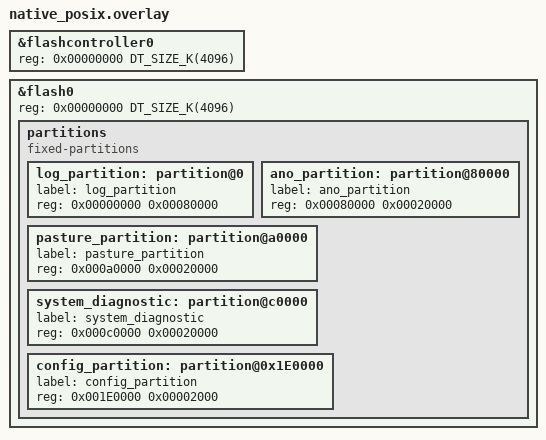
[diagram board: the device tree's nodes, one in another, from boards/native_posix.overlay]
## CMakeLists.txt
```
#
# Copyright (c) 2022 Nofence AS
#

cmake_minimum_required(VERSION 3.20.0)

list(APPEND ZEPHYR_EXTRA_MODULES
        ${CMAKE_CURRENT_SOURCE_DIR}/../../src/modules/collar_protocol
        )

find_package(Zephyr REQUIRED HINTS $ENV{ZEPHYR_BASE})
project(storage_controller)

zephyr_include_directories(${CMAKE_CURRENT_BINARY_DIR})
include_directories(${CMAKE_CURRENT_BINARY_DIR})

FILE(GLOB app_sources 
        ${CMAKE_CURRENT_SOURCE_DIR}/src/*.c 
        ${CMAKE_CURRENT_SOURCE_DIR}/mock/*.c 
        ${CMAKE_CURRENT_SOURCE_DIR}/../../src/events/storage/*.c
        ${CMAKE_CURRENT_SOURCE_DIR}/../../src/modules/storage_controller/storage.c
        ${CMAKE_CURRENT_SOURCE_DIR}/../../src/modules/storage_controller/fcb_ext/*.c
        ${CMAKE_CURRENT_SOURCE_DIR}/../../src/modules/storage/*.c
        ${CMAKE_CURRENT_SOURCE_DIR}/../../src/events/error_handler/*.c
        ${CMAKE_CURRENT_SOURCE_DIR}/../../src/events/messaging/*.c
)
target_sources(app PRIVATE ${app_sources})
target_include_directories(app PRIVATE ${APP_SOURCE})

zephyr_library_include_directories(
  ${CMAKE_CURRENT_SOURCE_DIR}/src/
  ${CMAKE_CURRENT_SOURCE_DIR}/mock/
  ${CMAKE_CURRENT_SOURCE_DIR}/../../src/modules/storage_controller/
  ${CMAKE_CURRENT_SOURCE_DIR}/../../src/modules/storage_controller/include
  ${CMAKE_CURRENT_SOURCE_DIR}/../../src/modules/storage_controller/fcb_ext
  ${CMAKE_CURRENT_SOURCE_DIR}/../../src/events/storage
  ${CMAKE_CURRENT_SOURCE_DIR}/../../src/events/error_handler
  ${CMAKE_CURRENT_SOURCE_DIR}/../../src/events/messaging
  ${CMAKE_CURRENT_SOURCE_DIR}/../../src/modules/messaging
  ${CMAKE_CURRENT_SOURCE_DIR}/../../include
  #${CMAKE_CURRENT_SOURCE_DIR}/../../src/modules/nf_settings/include
)
add_dependencies(app collar_protocol_headers)
```

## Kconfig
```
menu "APPLICATION_CODE"
	menu "Storage controller"
    	rsource "./../../src/modules/storage_controller/Kconfig"
	endmenu # Storage controller
	menu "ERROR_HANDLER"
    	rsource "./../../src/modules/error_handler/Kconfig"
	endmenu # ERROR_HANDLER
endmenu # APPLICATION CODE

menu "Zephyr Kernel"
source "Kconfig.zephyr"
endmenu
```

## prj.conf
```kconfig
CONFIG_ZTEST=y
CONFIG_ZTEST_MOCKING=y
CONFIG_ZTEST_STACKSIZE=8192

# Configuration required by Event Manager
CONFIG_EVENT_MANAGER=y
CONFIG_LINKER_ORPHAN_SECTION_PLACE=y
CONFIG_SYSTEM_WORKQUEUE_STACK_SIZE=16384
CONFIG_HEAP_MEM_POOL_SIZE=16384
CONFIG_REBOOT=y

CONFIG_MAIN_STACK_SIZE=8192
CONFIG_FLASH=y
CONFIG_FLASH_PAGE_LAYOUT=y
CONFIG_FLASH_MAP=y
CONFIG_FCB=y
CONFIG_NVS=n

# For rand()
CONFIG_NEWLIB_LIBC=y 

CONFIG_COLLAR_PROTOCOL=y
```

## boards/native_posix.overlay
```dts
&flashcontroller0 {
        reg = <0x00000000 DT_SIZE_K(4096)>;
};

&flash0 {
        reg = <0x00000000 DT_SIZE_K(4096)>;
        partitions {
                compatible = "fixed-partitions";
                #address-cells = <1>;
                #size-cells = <1>;

                log_partition: partition@0 {
                        label = "log_partition";
                        reg = <0x00000000 0x00080000>;
                };
                ano_partition: partition@80000 {
                        label = "ano_partition";
                        reg = <0x00080000 0x00020000>;
                };
                pasture_partition: partition@a0000 {
                        label = "pasture_partition";
                        reg = <0x000a0000 0x00020000>;
                };
                system_diagnostic: partition@c0000 {
                        label = "system_diagnostic";
                        reg = <0x000c0000 0x00020000>;
                };

                config_partition: partition@0x1E0000 {
                        label = "config_partition";
                        reg = <0x001E0000 0x00002000>;
                };
        };
};
```

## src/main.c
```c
/*
 * Copyright (c) 2022 Nofence AS
 */

#include <ztest.h>
#include "storage.h"
#include "storage_event.h"
#include "storage_helper.h"
#include "error_event.h"
#include "ano_structure.h"
#include "log_structure.h"
#include "pasture_structure.h"

/* Provide custom assert post action handler to handle the assertion on OOM
 * error in Event Manager.
 */
BUILD_ASSERT(!IS_ENABLED(CONFIG_ASSERT_NO_FILE_INFO));
void assert_post_action(const char *file, unsigned int line)
{
	printk("assert_post_action - file: %s (line: %u)\n", file, line);
}

void test_event_manager_init(void)
{
	zassert_false(event_manager_init(), "Error when initializing event manager");
}

void test_init(void)
{
	zassert_false(stg_init_storage_controller(), "Error when initializing storage controller.");
	init_dummy_pasture();
}

void test_main(void)
{
	/* Init FCBs and event manager setup. */
	ztest_test_suite(storage_init, ztest_unit_test(test_event_manager_init),
			 ztest_unit_test(test_init));
	ztest_run_test_suite(storage_init);

	/* Test log partition. */
	ztest_test_suite(storage_log_test, ztest_unit_test(test_log),
			 ztest_unit_test(test_log_padding),
			 ztest_unit_test(test_reboot_persistent_log),
			 ztest_unit_test(test_log_extended), ztest_unit_test(test_no_log_available),
			 ztest_unit_test(test_log_after_reboot), ztest_unit_test(test_double_clear),
			 ztest_unit_test(test_rotate_handling));
	ztest_run_test_suite(storage_log_test);

	/* Test ano partition. */
	ztest_test_suite(storage_ano_test, ztest_unit_test(test_ano_write_20_days),
			 ztest_unit_test(test_ano_write_sent), ztest_unit_test(test_ano_write_all),
			 ztest_unit_test(test_no_ano_available),
			 ztest_unit_test(test_reboot_persistent_ano));
	ztest_run_test_suite(storage_ano_test);

	/* Test pasture partition. */
	ztest_test_suite(storage_pasture_test, ztest_unit_test(test_pasture),
			 ztest_unit_test(test_reboot_persistent_pasture),
			 ztest_unit_test(test_pasture_extended_write_read),
			 ztest_unit_test(test_request_pasture_multiple),
			 ztest_unit_test(test_no_pasture_available));
	ztest_run_test_suite(storage_pasture_test);

	/* Test system diagnostic partition. */
	ztest_test_suite(storage_sys_diag_test, ztest_unit_test(test_sys_diag_log),
			 ztest_unit_test(test_reboot_persistent_system_diag));
	ztest_run_test_suite(storage_sys_diag_test);
}

static bool event_handler(const struct event_header *eh)
{
	if (is_error_event(eh)) {
		printk("Error detected. \n");
	}
	return false;
}

EVENT_LISTENER(test_main, event_handler);
EVENT_SUBSCRIBE(test_main, error_event);
EVENT_SUBSCRIBE(test_main, pasture_ready_event);
```

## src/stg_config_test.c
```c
/*
 * Copyright (c) 2022 Nofence AS
 */

#include <ztest.h>
#include "storage_helper.h"
#include "stg_config.h"
#include "pm_config.h"

void test_stg_init()
{
    zassert_equal(stg_config_init(), 0, "");
}
```

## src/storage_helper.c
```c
#include <ztest.h>
#include "storage.h"
#include "pasture_event.h"
#include "storage_helper.h"

#include "ano_structure.h"
#include "log_structure.h"
#include "pasture_structure.h"
```

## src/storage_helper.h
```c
/*
 * Copyright (c) 2022 Nofence AS
 */

#ifndef _STORAGE_HELPER_H_
#define _STORAGE_HELPER_H_

#include <ztest.h>
#include "storage.h"

void init_dummy_pasture(void);

/* Pasture tests. */
void test_pasture(void);
void test_pasture_extended_write_read(void);
void test_reboot_persistent_pasture(void);
void test_request_pasture_multiple(void);
void test_no_pasture_available(void);

/* Log tests. */
void test_log(void);
void test_log_extended(void);
void test_reboot_persistent_log(void);
void test_no_log_available(void);
void test_log_after_reboot(void);
void test_double_clear(void);
void test_rotate_handling(void);
void test_log_padding(void);

/* Ano tests. */
void test_ano_write_20_days(void);
void test_ano_write_sent(void);
void test_no_ano_available(void);
void test_ano_write_all(void);
void test_reboot_persistent_ano(void);

/* System diagnostic tests. */
void test_sys_diag_log(void);
void test_reboot_persistent_system_diag(void);

#endif /* _STORAGE_HELPER_H_ */
```

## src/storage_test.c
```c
/*
 * Copyright (c) 2022 Nofence AS
 */

#include <ztest.h>
#include "storage.h"
#include "storage_events.h"
#include "storage_helper.h"

#include "ano_structure.h"
#include "log_structure.h"
#include "pasture_structure.h"

K_SEM_DEFINE(write_log_ack_sem, 0, 1);
K_SEM_DEFINE(read_log_ack_sem, 0, 1);
K_SEM_DEFINE(consumed_log_ack_sem, 0, 1);

K_SEM_DEFINE(write_ano_ack_sem, 0, 1);
K_SEM_DEFINE(read_ano_ack_sem, 0, 1);
K_SEM_DEFINE(consumed_ano_ack_sem, 0, 1);

K_SEM_DEFINE(write_pasture_ack_sem, 0, 1);
K_SEM_DEFINE(read_pasture_ack_sem, 0, 1);
K_SEM_DEFINE(consumed_pasture_ack_sem, 0, 1);

int consumed_entries_counter = 0;

/* Used to check which partition was used, to release the correct semaphore. */
flash_partition_t cur_partition;

test_id_t cur_test_id = TEST_ID_INIT;

/* Provide custom assert post action handler to handle the assertion on OOM
 * error in Event Manager.
 */
BUILD_ASSERT(!IS_ENABLED(CONFIG_ASSERT_NO_FILE_INFO));
void assert_post_action(const char *file, unsigned int line)
{
	printk("assert_post_action - file: %s (line: %u)\n", file, line);
}

void test_event_manager_init(void)
{
	zassert_false(event_manager_init(),
		      "Error when initializing event manager");
}

void test_init(void)
{
	zassert_false(init_storage_controller(),
		      "Error when initializing storage controller.");

	k_sleep(K_SECONDS(30));
}

void test_append_log_data(void)
{
	write_log_data();
	int err = k_sem_take(&write_log_ack_sem, K_SECONDS(30));
	zassert_equal(err, 0,
		      "Test execution hanged waiting for write log ack.");
}

void test_empty_walk(void)
{
	/* Expect semaphore to hang, since we do not get any callbacks. */
	request_log_data();

	int err = k_sem_take(&read_log_ack_sem, K_SECONDS(30));
	zassert_not_equal(
		err, 0, "Test execution should hang waiting for read log ack.");

	/* We process the data further in event_handler. */

	err = k_sem_take(&consumed_log_ack_sem, K_SECONDS(30));
	zassert_not_equal(
		err, 0,
		"Test execution should hang waiting for consumed log ack.");
}

void test_read_log_data(void)
{
	/* First we request, then we get callback in event_handler when
	 * data is ready. There might be multiple entries since
	 * last read, so the event_handler can trigger several times
	 * with new entries. We just have to take care of the
	 * consume_event once we've consumed the data.
	 */
	request_log_data();
	int err = k_sem_take(&read_log_ack_sem, K_SECONDS(30));
	zassert_equal(err, 0,
		      "Test execution hanged waiting for read log ack.");

	/* We process the data further in event_handler. */

	err = k_sem_take(&consumed_log_ack_sem, K_SECONDS(30));
	zassert_equal(err, 0,
		      "Test execution hanged waiting for consumed log ack.");

	/* We know at this stage that we do not have more entries, test done. */
}

void test_multiple_writes_and_verify(void)
{
	/* Writes 14 log sectors, and 8 ano 
	 * sectors based on DEFINES in storage_helper.h. 
	 */
	int log_writes = 14;
	int ano_writes = 8;

	int err;

	/* LOG entires. */
	for (int i = 0; i < log_writes; i++) {
		write_log_data();

		err = k_sem_take(&write_log_ack_sem, K_SECONDS(30));
		zassert_equal(
			err, 0,
			"Test execution hanged waiting for write log ack.");
	}

	/* ANO entires. */
	for (int i = 0; i < ano_writes; i++) {
		write_ano_data();

		err = k_sem_take(&write_ano_ack_sem, K_SECONDS(30));
		zassert_equal(
			err, 0,
			"Test execution hanged waiting for write ano ack.");
	}

	consumed_entries_counter = 0;
	/* Walk LOG data entries. */
	request_log_data();

	/* Wait until the consume_data function triggered in event_handler
	 * is finished with all the entries. We know how many
	 * consumed_event acks we can expect.
	 */
	for (int i = 0; i < log_writes; i++) {
		err = k_sem_take(&consumed_log_ack_sem, K_SECONDS(30));
		zassert_equal(
			err, 0,
			"Test hanged waiting for multiple consumed log ack.");
	}
	/* Wait for event handler thread to process last consume_data. */
	k_sleep(K_SECONDS(60));

	/* Check if the consumed logic was processed 
	 * the correct number of times. The content is checked with zasserts
	 * within the consume_data function itself.
	 */
	zassert_equal(consumed_entries_counter, log_writes,
		      "Mismatched consumed log entries.");

	/* Perpare for walk ANO data entries. */
	consumed_entries_counter = 0;

	request_ano_data();
	for (int i = 0; i < ano_writes; i++) {
		err = k_sem_take(&consumed_ano_ack_sem, K_SECONDS(30));
		zassert_equal(
			err, 0,
			"Test hanged waiting for multiple consumed ano ack.");
	}
	/* Wait for event handler thread to process last consume_data. */
	k_sleep(K_SECONDS(60));
	zassert_equal(consumed_entries_counter, ano_writes,
		      "Mismatched consumed ano entries.");
}

void test_append_too_many(void)
{
	/* Used as ID written on each sector. */
	consumed_entries_counter = 0;

	/* It's difficult to calculate precicely how many reads
	 * will be performed, due to padding within the FLASH_AREA partition.
	 * Assume we have mem_rec structure, which consists of 264 bytes and we
	 * have 0x20000 (128kb) memory, we can estimate 496.484848 - 1 reads,
	 * however, FCB adds padding inbetween entries as well as header,
	 * since the correct number of reads with mem_rec seems to be around 
	 * 470.
	 */
	int num_log_sectors = 1024;
	int num_ano_sectors = 256;

	int err;

	for (int i = 0; i < num_log_sectors; i++) {
		write_log_data();
		err = k_sem_take(&write_log_ack_sem, K_SECONDS(30));
		zassert_equal(
			err, 0,
			"Test execution hanged waiting for write log ack.");
	}

	/* Used as ID written on each sector. */
	consumed_entries_counter = 0;

	for (int i = 0; i < num_ano_sectors; i++) {
		write_ano_data();
		err = k_sem_take(&write_ano_ack_sem, K_SECONDS(30));
		zassert_equal(
			err, 0,
			"Test execution hanged waiting for write ano ack.");
	}
}

/** @brief Checks what happens if we try to read after there's a long time
*          since we've read previously.
*/
void test_read_too_many(void)
{
	/* It's difficult to calculate precicely how many reads
	 * will be performed, due to padding within the FLASH_AREA partition.
	 * Assume we have mem_rec structure, which consists of 264 bytes and we
	 * have 0x20000 (128kb) memory, we can estimate 496.484848 - 1 reads,
	 * however, FCB adds padding inbetween entries as well as header,
	 * since the correct number of reads with mem_rec seems to be around 
	 * 470.
	 */
	int log_writes = 1024;
	int ano_writes = 256;

	int err;

	consumed_entries_counter = 0;
	/* Walk LOG data entries. */
	request_log_data();

	/* Wait until the consume_data function triggered in event_handler
	 * is finished with all the entries. We know how many
	 * consumed_event acks we can expect.
	 */
	for (int i = 0; i < log_writes; i++) {
		err = k_sem_take(&consumed_log_ack_sem, K_SECONDS(30));
		zassert_equal(
			err, 0,
			"Test hanged waiting for multiple consumed log ack.");
	}
	/* Wait for event handler thread to process last consume_data. */
	k_sleep(K_SECONDS(60));

	/* Check if the consumed logic was processed 
	 * the correct number of times. The content is checked with zasserts
	 * within the consume_data function itself.
	 */
	zassert_equal(consumed_entries_counter, log_writes,
		      "Mismatched consumed log entries.");

	/* Perpare for walk ANO data entries. */
	consumed_entries_counter = 0;

	request_ano_data();
	for (int i = 0; i < ano_writes; i++) {
		err = k_sem_take(&consumed_ano_ack_sem, K_SECONDS(30));
		zassert_equal(
			err, 0,
			"Test hanged waiting for multiple consumed ano ack.");
	}
	/* Wait for event handler thread to process last consume_data. */
	k_sleep(K_SECONDS(60));
	zassert_equal(consumed_entries_counter, ano_writes,
		      "Mismatched consumed ano entries.");
}

void test_clear_fcbs(void)
{
	int err;

	zassert_equal(clear_fcb_sectors(STG_PARTITION_LOG), 0, "");
	zassert_equal(clear_fcb_sectors(STG_PARTITION_ANO), 0, "");

	k_sleep(K_SECONDS(60));

	/* Read and see that the semaphores lock, since we do not get
	 * callbacks due to empty FCBs.
	 */
	request_log_data();
	err = k_sem_take(&read_log_ack_sem, K_SECONDS(30));
	zassert_not_equal(err, 0, "");
	err = k_sem_take(&consumed_log_ack_sem, K_SECONDS(30));
	zassert_not_equal(err, 0, "");

	request_ano_data();
	err = k_sem_take(&read_log_ack_sem, K_SECONDS(30));
	zassert_not_equal(err, 0, "");
	err = k_sem_take(&consumed_log_ack_sem, K_SECONDS(30));
	zassert_not_equal(err, 0, "");
}

void setup_take_semaphores_reset_counter(void)
{
	/* Used when counting entries in walks. */
	consumed_entries_counter = 0;

	/* Take semaphores to ensure they are 
	 * taken prior to the tests that need them. 
	 */
	k_sem_take(&read_log_ack_sem, K_SECONDS(30));
	k_sem_take(&read_ano_ack_sem, K_SECONDS(30));

	k_sem_take(&consumed_log_ack_sem, K_SECONDS(30));
	k_sem_take(&consumed_ano_ack_sem, K_SECONDS(30));

	k_sem_take(&write_log_ack_sem, K_SECONDS(30));
	k_sem_take(&write_ano_ack_sem, K_SECONDS(30));
}

void teardown_tidy_threads(void)
{
	/* Ensure other threads in use have time to finish what they're doing.
	 * This does makes no difference to threads that are coopartive (<-1)
	 */
	k_sleep(K_SECONDS(60));
}

void test_main(void)
{
	ztest_test_suite(
		storage_controller_tests,
		ztest_unit_test(test_event_manager_init),
		ztest_unit_test(test_init),
		ztest_unit_test_setup_teardown(
			test_empty_walk, setup_take_semaphores_reset_counter,
			teardown_tidy_threads),
		ztest_unit_test_setup_teardown(
			test_append_log_data,
			setup_take_semaphores_reset_counter,
			teardown_tidy_threads),
		ztest_unit_test_setup_teardown(
			test_read_log_data, setup_take_semaphores_reset_counter,
			teardown_tidy_threads),
		ztest_unit_test_setup_teardown(
			test_multiple_writes_and_verify,
			setup_take_semaphores_reset_counter,
			teardown_tidy_threads),
		ztest_unit_test_setup_teardown(
			test_append_too_many,
			setup_take_semaphores_reset_counter,
			teardown_tidy_threads),
		ztest_unit_test_setup_teardown(
			test_read_too_many, setup_take_semaphores_reset_counter,
			teardown_tidy_threads),
		ztest_unit_test_setup_teardown(
			test_clear_fcbs, setup_take_semaphores_reset_counter,
			teardown_tidy_threads));
	ztest_run_test_suite(storage_controller_tests);

	ztest_test_suite(
		storage_controller_test_pasture,
		ztest_unit_test_setup_teardown(
			test_pasture_write, setup_take_semaphores_reset_counter,
			teardown_tidy_threads),
		ztest_unit_test_setup_teardown(
			test_pasture_read, setup_take_semaphores_reset_counter,
			teardown_tidy_threads),
		ztest_unit_test_setup_teardown(
			test_pasture_log_ano_write_read,
			setup_take_semaphores_reset_counter,
			teardown_tidy_threads),
		ztest_unit_test_setup_teardown(
			test_pasture_extended_write_read,
			setup_take_semaphores_reset_counter,
			teardown_tidy_threads));

	/*ztest_test_suite(storage_controller_test_pasture,
			 ztest_unit_test(test_event_manager_init),
			 ztest_unit_test(test_init),
			 ztest_unit_test_setup_teardown(
				 test_pasture_log_ano_write_read,
				 setup_take_semaphores_reset_counter,
				 teardown_tidy_threads),
			 ztest_unit_test_setup_teardown(
				 test_pasture_extended_write_read,
				 setup_take_semaphores_reset_counter,
				 teardown_tidy_threads));*/

	ztest_run_test_suite(storage_controller_test_pasture);
}

static bool event_handler(const struct event_header *eh)
{
	if (is_stg_ack_write_event(eh)) {
		struct stg_ack_write_event *ev = cast_stg_ack_write_event(eh);
		if (ev->partition == STG_PARTITION_LOG) {
			k_sem_give(&write_log_ack_sem);

			if (write_log_ptr != NULL) {
				k_free(write_log_ptr);
				write_log_ptr = NULL;
			}

		} else if (ev->partition == STG_PARTITION_ANO) {
			k_sem_give(&write_ano_ack_sem);

			if (write_ano_ptr != NULL) {
				k_free(write_ano_ptr);
				write_ano_ptr = NULL;
			}

		} else if (ev->partition == STG_PARTITION_PASTURE) {
			k_sem_give(&write_pasture_ack_sem);

			if (write_pasture_ptr != NULL) {
				k_free(write_pasture_ptr);
				write_pasture_ptr = NULL;
			}
		} else {
			zassert_unreachable(
				"Unexpected ack write partition recieved.");
		}
		return false;
	}
	if (is_stg_ack_read_event(eh)) {
		struct stg_ack_read_event *ev = cast_stg_ack_read_event(eh);

		if (ev->partition == STG_PARTITION_LOG) {
			k_sem_give(&read_log_ack_sem);
			consume_data(ev);
		} else if (ev->partition == STG_PARTITION_ANO) {
			k_sem_give(&read_ano_ack_sem);
			consume_data(ev);
		} else if (ev->partition == STG_PARTITION_PASTURE) {
			k_sem_give(&read_pasture_ack_sem);
			/* Consume the data, where we also publish consumed events
			 * once we're done with the data. This continues the walk
			 * process and can trigger further read acks.
			 */
			consume_data(ev);
		} else {
			zassert_unreachable(
				"Unexpected ack write partition recieved.");
		}

		/* After contents have been consumed successfully, 
		 * notify the storage controller to continue walk if there
		 * are any new entries.
		 */
		struct stg_consumed_read_event *ev_read =
			new_stg_consumed_read_event();
		EVENT_SUBMIT(ev_read);

		/* Sleep thread so storage controller can catch the consume
		 * event and process further reads.
		 */
		k_sleep(K_SECONDS(1));
		return false;
	}
	if (is_stg_consumed_read_event(eh)) {
		if (cur_partition == STG_PARTITION_LOG) {
			k_sem_give(&consumed_log_ack_sem);
		} else if (cur_partition == STG_PARTITION_ANO) {
			k_sem_give(&consumed_ano_ack_sem);
		} else if (cur_partition == STG_PARTITION_PASTURE) {
			k_sem_give(&consumed_pasture_ack_sem);
		} else {
			zassert_unreachable(
				"Unexpected ack read partition recieved.");
		}
		return false;
	}
	return false;
}

EVENT_LISTENER(test_main, event_handler);

EVENT_SUBSCRIBE(test_main, stg_ack_write_event);
EVENT_SUBSCRIBE(test_main, stg_ack_read_event);
EVENT_SUBSCRIBE(test_main, stg_consumed_read_event);
```

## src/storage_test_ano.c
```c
/*
 * Copyright (c) 2022 Nofence AS
 */

#include <ztest.h>
#include "storage.h"
#include "storage_helper.h"

#include "ano_structure.h"
#include "log_structure.h"
#include "pasture_structure.h"

#include "pm_config.h"
#include <stdlib.h>

#include "UBX.h"

UBX_MGA_ANO_RAW_t dummy_ano = { .mga_ano.year = 22, .mga_ano.month = 4, .mga_ano.day = 5 };
size_t dummy_ano_len = sizeof(UBX_MGA_ANO_RAW_t);

uint16_t expected_valid_day = 5;

int read_callback_ano(uint8_t *data, size_t len)
{
	UBX_MGA_ANO_RAW_t *ano_frame = (UBX_MGA_ANO_RAW_t *)data;
	zassert_equal(len, dummy_ano_len, "");
	zassert_mem_equal(ano_frame, &dummy_ano, len, "");
	return 0;
}

int read_callback_inc_days(uint8_t *data, size_t len)
{
	int err = read_callback_ano(data, len);
	dummy_ano.mga_ano.day++;
	return err;
}

/** @brief Writes ano data, where each frame is one day.
 *         So it will write from day 5 to 25, and checks if we read all
 *         entries if read_from_boot_entry == false.
 */
void test_ano_write_20_days(void)
{
	zassert_equal(stg_clear_partition(STG_PARTITION_ANO), 0, "");

	dummy_ano.mga_ano.day = 5;
	for (int i = 0; i < 20; i++) {
		zassert_equal(stg_write_ano_data((uint8_t *)&dummy_ano, dummy_ano_len), 0,
			      "Write ano error.");
		dummy_ano.mga_ano.day++;
	}

	dummy_ano.mga_ano.day = 5;

	zassert_equal(stg_read_ano_data(read_callback_inc_days, false, 0), 0, "Read ano error.");
}

/** @brief Writes ano data, reads, write and then read again to see if it continues
 *         where it left off. Tests if we can continue where we left of with
 *         read_from_boot_entry == false.
 */
void test_ano_write_sent(void)
{
	zassert_equal(stg_clear_partition(STG_PARTITION_ANO), 0, "");

	dummy_ano.mga_ano.day = 5;
	for (int i = 0; i < 10; i++) {
		zassert_equal(stg_write_ano_data((uint8_t *)&dummy_ano, dummy_ano_len), 0,
			      "Write ano error.");
		dummy_ano.mga_ano.day++;
	}

	dummy_ano.mga_ano.day = 5;

	zassert_equal(stg_read_ano_data(read_callback_inc_days, false, 0), 0, "Read ano error.");

	/* Continue to write where it left off. */
	dummy_ano.mga_ano.day = 15;
	for (int i = 0; i < 10; i++) {
		zassert_equal(stg_write_ano_data((uint8_t *)&dummy_ano, dummy_ano_len), 0,
			      "Write ano error.");
		dummy_ano.mga_ano.day++;
	}

	/* We now expect us to read from 15 to 25, not 5 to 25. */
	dummy_ano.mga_ano.day = 15;
	zassert_equal(stg_read_ano_data(read_callback_inc_days, false, 0), 0, "Read ano error.");
}

/** @brief Writes ano data, updates the boot pointer 
 *         by simulating a reboot, and then read again from
 *         that pointer. We write 1 to 30 days, so we expect
 *         everything from 5-30 to be the callbacked results.
 */
void test_ano_write_all(void)
{
	zassert_equal(stg_clear_partition(STG_PARTITION_ANO), 0, "");

	dummy_ano.mga_ano.day = 1;
	for (int i = 0; i < 30; i++) {
		zassert_equal(stg_write_ano_data((uint8_t *)&dummy_ano, dummy_ano_len), 0,
			      "Write ano error.");
		dummy_ano.mga_ano.day++;
	}

	/* Simualte reboot. We check here if we have valid ANO data, which
	 * means date_time_now should be called 1,2,3,4,5, 5 times until it finds
	 * a valid entry containing a day greater or equal than 5th. 
	 */
	ztest_returns_value(date_time_now, 0);
	ztest_returns_value(date_time_now, 0);
	ztest_returns_value(date_time_now, 0);
	ztest_returns_value(date_time_now, 0);
	ztest_returns_value(date_time_now, 0);
	int err = stg_fcb_reset_and_init();
	zassert_equal(err, 0, "Error simulating reboot and FCB resets.");

	dummy_ano.mga_ano.day = 5;

	zassert_equal(stg_read_ano_data(read_callback_inc_days, true, 0), 0, "Read ano error.");
}

void test_reboot_persistent_ano(void)
{
	ztest_returns_value(date_time_now, 0);
	zassert_equal(stg_clear_partition(STG_PARTITION_ANO), 0, "");
	dummy_ano.mga_ano.year = 22;
	zassert_equal(stg_write_ano_data((uint8_t *)&dummy_ano, dummy_ano_len), 0,
		      "Write ano error.");

	/* Reset FCB, pretending to reboot. Checks if persistent storage
	 * works. Should get the expected read value from the written one above.
	 */
	int err = stg_fcb_reset_and_init();
	zassert_equal(err, 0, "Error simulating reboot and FCB resets.");

	zassert_equal(stg_read_ano_data(read_callback_ano, true, 0), 0, "Read ano error.");
}

/** @brief Test to check that the fcb_offset_last_n function works
 *         if there have been no writes between the requests.
 */
void test_no_ano_available(void)
{
	/* Clear partition. */
	zassert_equal(stg_clear_partition(STG_PARTITION_ANO), 0, "");

	/* Read. */
	zassert_equal(stg_read_ano_data(read_callback_ano, false, 0), -ENODATA,
		      "Read ano should return -ENODATA.");
}
```

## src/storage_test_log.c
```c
/*
 * Copyright (c) 2022 Nofence AS
 */

#include <ztest.h>
#include "storage.h"
#include "storage_helper.h"
#include "log_structure.h"

#include "pm_config.h"
#include <stdlib.h>

log_rec_t dummy_log = { .seq_1.has_usBatteryVoltage = true,
			.seq_1.usBatteryVoltage = 3300,

			.seq_2.has_bme280 = true,
			.seq_2.bme280.ulHumidity = 40,
			.seq_2.bme280.ulPressure = 105,
			.seq_2.bme280.ulTemperature = 25 };

size_t dummy_log_len = sizeof(log_rec_t);

int read_callback_log(uint8_t *data, size_t len)
{
	zassert_equal(len, dummy_log_len, "");
	zassert_mem_equal((log_rec_t *)data, &dummy_log, len, "");
	return 0;
}

uint8_t padding_dummy_bytes[3] = { 0x00, 0x01, 0x03 };
int read_callback_padding_log(uint8_t *data, size_t len)
{
	/* We expect 3 more bytes of padding to the with length
	 *  in data with size of 5. 
	 */
	zassert_equal(len, 8, "");

	size_t payload_size = (uint16_t)((data[1] << 8) + (data[0] & 0x00ff));
	zassert_equal(payload_size, 3, "");
	zassert_mem_equal(&padding_dummy_bytes[0], &data[2], payload_size, "");
	return 0;
}

static int num_multiple_log_reads = 0;
static int expected_log_entries = 5;

int read_callback_multiple_log(uint8_t *data, size_t len)
{
	num_multiple_log_reads++;
	return read_callback_log(data, len);
}

void test_log(void)
{
	zassert_equal(stg_write_log_data((uint8_t *)&dummy_log, dummy_log_len), 0,
		      "Write log error.");
	zassert_equal(stg_read_log_data(read_callback_log, 0), 0, "Read log error.");
	zassert_false(stg_clear_partition(STG_PARTITION_LOG), "");
}

void test_log_padding(void)
{
	uint8_t byte_array[5];

	size_t len = sizeof(padding_dummy_bytes);

	byte_array[0] = (uint8_t)len;
	byte_array[1] = (uint8_t)(len >> 8);

	zassert_equal(byte_array[0], 3, "");
	zassert_equal(byte_array[1], 0, "");

	memcpy(&byte_array[2], &padding_dummy_bytes[0], len);

	zassert_false(stg_clear_partition(STG_PARTITION_LOG), "");
	zassert_false(stg_write_log_data(byte_array, sizeof(byte_array)), "");
	zassert_false(stg_read_log_data(read_callback_padding_log, 0), "");
	zassert_false(stg_clear_partition(STG_PARTITION_LOG), "");
}

void test_log_extended(void)
{
	for (int i = 0; i < expected_log_entries; i++) {
		zassert_equal(stg_write_log_data((uint8_t *)&dummy_log, dummy_log_len), 0,
			      "Write log error.");
	}
	zassert_equal(stg_read_log_data(read_callback_multiple_log, 0), 0, "Read log error.");
	zassert_equal(num_multiple_log_reads, expected_log_entries, "");
}

void test_reboot_persistent_log(void)
{
	zassert_equal(stg_write_log_data((uint8_t *)&dummy_log, dummy_log_len), 0,
		      "Write log error.");

	/* Clear ANO partition so that we do not call date_time. */
	zassert_false(stg_clear_partition(STG_PARTITION_ANO), "");

	/* Reset FCB, pretending to reboot. Checks if persistent storage
	 * works. Should get the expected read value from the written one above.
	 */
	int err = stg_fcb_reset_and_init();
	zassert_equal(err, 0, "Error simulating reboot and FCB resets.");

	zassert_equal(stg_read_log_data(read_callback_log, 0), 0, "Read log error.");
}

/** @brief Test to check that we get ENODATA if there are no data available
 *         on the partition.
 */
void test_no_log_available(void)
{
	/* Clear partition. */
	zassert_equal(stg_clear_partition(STG_PARTITION_LOG), 0, "");

	/* Read. */
	zassert_equal(stg_read_log_data(read_callback_log, 0), -ENODATA,
		      "Read log should return -ENODATA.");
}

/** @brief Test to see nothing happens and we get no error if we try to clear
 *         an empty fcb.
 */
void test_double_clear(void)
{
	/* Clear partition. */
	zassert_equal(stg_clear_partition(STG_PARTITION_LOG), 0, "");
	zassert_equal(stg_clear_partition(STG_PARTITION_LOG), 0, "");
}

void test_rotate_handling(void)
{
	/* Write entries greater than partition size. */
	uint32_t num_entries = (PM_LOG_PARTITION_SIZE / sizeof(log_rec_t)) + 1;
	for (int i = 0; i < num_entries; i++) {
		zassert_equal(stg_write_log_data((uint8_t *)&dummy_log, dummy_log_len), 0,
			      "Write log error.");
	}

	uint32_t expected_entries = get_num_entries(STG_PARTITION_LOG);
	num_multiple_log_reads = 0;

	zassert_equal(stg_read_log_data(read_callback_multiple_log, 0), 0, "");
	zassert_equal(num_multiple_log_reads, expected_entries, "");

	/* Write 50 times since we know we have to rotate once. */
	for (int i = 0; i < 50; i++) {
		zassert_equal(stg_write_log_data((uint8_t *)&dummy_log, dummy_log_len), 0,
			      "Write log error.");
	}

	expected_entries = 50;
	num_multiple_log_reads = 0;

	zassert_equal(stg_read_log_data(read_callback_multiple_log, 0), 0, "");
	zassert_equal(num_multiple_log_reads, expected_entries, "");
}

/** @brief Checks if it remembers the entries being read before.
 */
void test_log_after_reboot(void)
{
	/* Clear partition. */
	zassert_equal(stg_clear_partition(STG_PARTITION_LOG), 0, "");

	/* Write 10 entries. */
	for (int i = 0; i < 10; i++) {
		zassert_equal(stg_write_log_data((uint8_t *)&dummy_log, dummy_log_len), 0,
			      "Write log error.");
	}

	/* Read and expect 4 entries. */
	num_multiple_log_reads = 0;
	zassert_equal(stg_read_log_data(read_callback_multiple_log, 4), 0, "");
	zassert_equal(num_multiple_log_reads, 4, "");

	/* Simulate reboot. */
	int err = stg_fcb_reset_and_init();
	zassert_equal(err, 0, "Error simulating reboot and FCB resets.");

	/* We know the pointer is not persistent, so we still expect 10 entries. */
	num_multiple_log_reads = 0;
	zassert_equal(stg_read_log_data(read_callback_multiple_log, 0), 0, "");
	zassert_equal(num_multiple_log_reads, 10, "");

	/* We're done reading, erase contents since we're done with it. */
	zassert_equal(stg_clear_partition(STG_PARTITION_LOG), 0, "");

	/* Simulate reboot. */
	err = stg_fcb_reset_and_init();
	zassert_equal(err, 0, "Error simulating reboot and FCB resets.");

	/* We should now have 0 entries remaining due to clear fcb
	 * partition. Should return -ENODATA. 
	 */
	zassert_equal(stg_read_log_data(read_callback_multiple_log, 0), -ENODATA, "");
}
```

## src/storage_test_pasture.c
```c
/*
 * Copyright (c) 2022 Nofence AS
 */

#include <ztest.h>
#include "storage.h"
#include "storage_helper.h"

#include "ano_structure.h"
#include "log_structure.h"
#include "pasture_structure.h"

#include "pm_config.h"
#include <stdlib.h>

#include "storage.h"

pasture_t pasture;

void init_dummy_pasture(void)
{
	pasture.m.ul_total_fences = 2;

	pasture.fences[0].m.fence_no = 0;
	pasture.fences[0].m.n_points = 2;
	pasture.fences[0].coordinates[0].s_x_dm = 1;
	pasture.fences[0].coordinates[0].s_y_dm = 2;
	pasture.fences[0].coordinates[1].s_x_dm = 3;
	pasture.fences[0].coordinates[1].s_y_dm = 4;

	pasture.fences[1].m.fence_no = 1;
	pasture.fences[1].m.n_points = 3;
	pasture.fences[1].coordinates[0].s_x_dm = 1;
	pasture.fences[1].coordinates[0].s_y_dm = 2;
	pasture.fences[1].coordinates[1].s_x_dm = 3;
	pasture.fences[1].coordinates[1].s_y_dm = 4;
	pasture.fences[1].coordinates[2].s_x_dm = 5;
	pasture.fences[1].coordinates[2].s_y_dm = 6;
}

int read_callback_pasture(uint8_t *data, size_t len)
{
	zassert_equal(len, sizeof(pasture_t), "");
	zassert_mem_equal((pasture_t *)data, &pasture, len, "");
	return 0;
}

void test_pasture(void)
{
	zassert_equal(stg_write_pasture_data((uint8_t *)&pasture, sizeof(pasture)), 0,
		      "Write pasture error.");
	zassert_equal(stg_read_pasture_data(read_callback_pasture), 0, "Read pasture error.");
}

void test_pasture_extended_write_read(void)
{
	for (int i = 0; i < 5; i++) {
		zassert_equal(stg_write_pasture_data((uint8_t *)&pasture, sizeof(pasture)), 0,
			      "Write pasture error.");
	}
	zassert_equal(stg_read_pasture_data(read_callback_pasture), 0, "Read pasture error.");
}

void test_reboot_persistent_pasture(void)
{
	zassert_equal(stg_write_pasture_data((uint8_t *)&pasture, sizeof(pasture)), 0,
		      "Write pasture error.");

	/* Clear ANO partition so that we do not call date_time. */
	zassert_false(stg_clear_partition(STG_PARTITION_ANO), "");

	/* Reset FCB, pretending to reboot. Checks if persistent storage
	 * works. Should get the expected read value from the written one above.
	 */
	int err = stg_fcb_reset_and_init();
	zassert_equal(err, 0, "Error simulating reboot and FCB resets.");

	zassert_equal(stg_read_pasture_data(read_callback_pasture), 0, "Read pasture error.");
}

/** @brief Test to check that the fcb_offset_last_n function works
 *         if there have been no writes between the requests.
 */
void test_request_pasture_multiple(void)
{
	zassert_equal(stg_write_pasture_data((uint8_t *)&pasture, sizeof(pasture)), 0,
		      "Write pasture error.");

	zassert_equal(stg_read_pasture_data(read_callback_pasture), 0, "Read pasture error.");
	zassert_equal(stg_read_pasture_data(read_callback_pasture), 0, "Read pasture error.");
	zassert_equal(stg_read_pasture_data(read_callback_pasture), 0, "Read pasture error.");
	zassert_equal(stg_read_pasture_data(read_callback_pasture), 0, "Read pasture error.");
}

/** @brief Test to check that the fcb_offset_last_n function works
 *         if there have been no writes between the requests.
 */
void test_no_pasture_available(void)
{
	/* Clear partition. */
	zassert_equal(stg_clear_partition(STG_PARTITION_PASTURE), 0, "");

	/* Read. */
	zassert_equal(stg_read_pasture_data(read_callback_pasture), -ENODATA,
		      "Read pasture should return -ENODATA.");
}
```

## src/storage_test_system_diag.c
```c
/*
 * Copyright (c) 2022 Nofence AS
 */

#include <ztest.h>
#include "storage.h"
#include "storage_helper.h"
#include "system_diagnostic_structure.h"

#include "pm_config.h"
#include <stdlib.h>

system_diagnostic_t dummy_sys_diag = {
	.error_code = -ENOMEM,
};

size_t dummy_sys_diag_len = sizeof(system_diagnostic_t);

int read_callback_sys_log(uint8_t *data, size_t len)
{
	zassert_equal(len, dummy_sys_diag_len, "");
	zassert_mem_equal((system_diagnostic_t *)data, &dummy_sys_diag, len, "");
	return 0;
}

void test_sys_diag_log(void)
{
	zassert_equal(stg_write_system_diagnostic_log((uint8_t *)&dummy_sys_diag,
						      dummy_sys_diag_len),
		      0, "Write system diagnostic error.");
	zassert_equal(stg_read_system_diagnostic_log(read_callback_sys_log, 0), 0,
		      "Read system diagnostic error.");
}

void test_reboot_persistent_system_diag(void)
{
	zassert_equal(stg_write_system_diagnostic_log((uint8_t *)&dummy_sys_diag,
						      dummy_sys_diag_len),
		      0, "Write system diagnostic error.");

	/* Clear ANO partition so that we do not call date_time. */
	zassert_false(stg_clear_partition(STG_PARTITION_ANO), "");

	int err = stg_fcb_reset_and_init();
	zassert_equal(err, 0, "Error simulating reboot and FCB resets.");
	zassert_equal(stg_read_system_diagnostic_log(read_callback_sys_log, 0), 0,
		      "Read system diagnostic error.");
}
```
